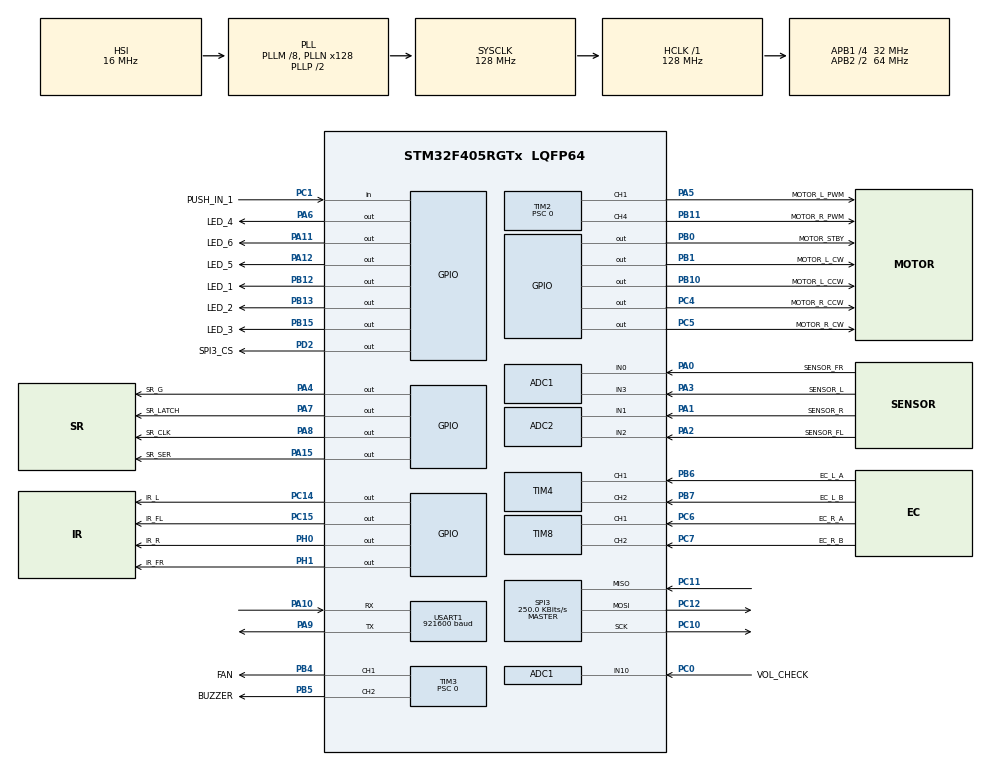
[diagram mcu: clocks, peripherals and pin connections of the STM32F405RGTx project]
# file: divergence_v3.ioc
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ADC1.Channel-0\#ChannelRegularConversion=ADC_CHANNEL_3
ADC1.Channel-1\#ChannelRegularConversion=ADC_CHANNEL_0
ADC1.Channel-2\#ChannelRegularConversion=ADC_CHANNEL_3
ADC1.Channel-3\#ChannelRegularConversion=ADC_CHANNEL_0
ADC1.Channel-4\#ChannelRegularConversion=ADC_CHANNEL_10
ADC1.ClockPrescaler=ADC_CLOCK_SYNC_PCLK_DIV4
ADC1.DiscontinuousConvMode=ENABLE
ADC1.NbrOfConversion=5
ADC1.NbrOfConversionFlag=1
ADC1.Rank-0\#ChannelRegularConversion=1
ADC1.Rank-1\#ChannelRegularConversion=2
ADC1.Rank-2\#ChannelRegularConversion=3
ADC1.Rank-3\#ChannelRegularConversion=4
ADC1.Rank-4\#ChannelRegularConversion=5
ADC1.SamplingTime-0\#ChannelRegularConversion=ADC_SAMPLETIME_84CYCLES
ADC1.SamplingTime-1\#ChannelRegularConversion=ADC_SAMPLETIME_84CYCLES
ADC1.SamplingTime-2\#ChannelRegularConversion=ADC_SAMPLETIME_84CYCLES
ADC1.SamplingTime-3\#ChannelRegularConversion=ADC_SAMPLETIME_84CYCLES
ADC1.SamplingTime-4\#ChannelRegularConversion=ADC_SAMPLETIME_84CYCLES
ADC1.ScanConvMode=ENABLE
ADC1.master=1
ADC2.Channel-0\#ChannelRegularConversion=ADC_CHANNEL_2
ADC2.Channel-1\#ChannelRegularConversion=ADC_CHANNEL_1
ADC2.Channel-2\#ChannelRegularConversion=ADC_CHANNEL_2
ADC2.Channel-3\#ChannelRegularConversion=ADC_CHANNEL_1
ADC2.ClockPrescaler=ADC_CLOCK_SYNC_PCLK_DIV4
ADC2.DiscontinuousConvMode=ENABLE
ADC2.NbrOfConversion=4
ADC2.NbrOfConversionFlag=1
ADC2.Rank-0\#ChannelRegularConversion=1
ADC2.Rank-1\#ChannelRegularConversion=2
ADC2.Rank-2\#ChannelRegularConversion=3
ADC2.Rank-3\#ChannelRegularConversion=4
ADC2.SamplingTime-0\#ChannelRegularConversion=ADC_SAMPLETIME_84CYCLES
ADC2.SamplingTime-1\#ChannelRegularConversion=ADC_SAMPLETIME_84CYCLES
ADC2.SamplingTime-2\#ChannelRegularConversion=ADC_SAMPLETIME_84CYCLES
ADC2.SamplingTime-3\#ChannelRegularConversion=ADC_SAMPLETIME_84CYCLES
ADC2.ScanConvMode=ENABLE
Dma.Request0=SPI3_RX
Dma.Request1=SPI3_TX
Dma.SPI3_RX.0.Direction=DMA_PERIPH_TO_MEMORY
Dma.SPI3_RX.0.FIFOMode=DMA_FIFOMODE_DISABLE
Dma.SPI3_RX.0.Instance=DMA1_Stream0
Dma.SPI3_RX.0.MemDataAlignment=DMA_MDATAALIGN_BYTE
Dma.SPI3_RX.0.MemInc=DMA_MINC_ENABLE
Dma.SPI3_RX.0.Mode=DMA_NORMAL
Dma.SPI3_RX.0.PeriphDataAlignment=DMA_PDATAALIGN_BYTE
Dma.SPI3_RX.0.PeriphInc=DMA_PINC_DISABLE
Dma.SPI3_RX.0.Priority=DMA_PRIORITY_VERY_HIGH
Dma.SPI3_TX.1.Direction=DMA_MEMORY_TO_PERIPH
Dma.SPI3_TX.1.FIFOMode=DMA_FIFOMODE_DISABLE
Dma.SPI3_TX.1.Instance=DMA1_Stream5
Dma.SPI3_TX.1.MemDataAlignment=DMA_MDATAALIGN_BYTE
Dma.SPI3_TX.1.MemInc=DMA_MINC_DISABLE
Dma.SPI3_TX.1.Mode=DMA_NORMAL
Dma.SPI3_TX.1.PeriphDataAlignment=DMA_PDATAALIGN_BYTE
Dma.SPI3_TX.1.PeriphInc=DMA_PINC_DISABLE
Dma.SPI3_TX.1.Priority=DMA_PRIORITY_VERY_HIGH
Mcu.Family=STM32F4
Mcu.Name=STM32F405RGTx
Mcu.Package=LQFP64
NVIC.DMA1_Stream0_IRQn=true\:0\:0\:false\:false\:true\:false\:true\:true
NVIC.DMA1_Stream5_IRQn=true\:0\:0\:false\:false\:true\:false\:true\:true
NVIC.PriorityGroup=NVIC_PRIORITYGROUP_4
NVIC.SPI3_IRQn=true\:0\:0\:false\:false\:true\:true\:true\:true
NVIC.TIM6_DAC_IRQn=true\:0\:0\:false\:false\:true\:true\:true\:true
PA0-WKUP.GPIO_Label=SENSOR_FR
PA0-WKUP.Signal=ADCx_IN0
PA1.GPIO_Label=SENSOR_R
PA1.Signal=ADCx_IN1
PA10.Mode=Asynchronous
PA10.Signal=USART1_RX
PA11.GPIO_Label=LED_6
PA11.Signal=GPIO_Output
PA12.GPIO_Label=LED_5
PA12.Signal=GPIO_Output
PA13.Signal=SYS_JTMS-SWDIO
PA14.Signal=SYS_JTCK-SWCLK
PA15.GPIO_Label=SR_SER
PA15.Signal=GPIO_Output
PA2.GPIO_Label=SENSOR_FL
PA2.Signal=ADCx_IN2
PA3.GPIO_Label=SENSOR_L
PA3.Signal=ADCx_IN3
PA4.GPIO_Label=SR_G
PA4.Signal=GPIO_Output
PA5.GPIO_Label=MOTOR_L_PWM
PA5.Signal=S_TIM2_CH1_ETR
PA6.GPIO_Label=LED_4
PA6.Signal=GPIO_Output
PA7.GPIO_Label=SR_LATCH
PA7.Signal=GPIO_Output
PA8.GPIO_Label=SR_CLK
PA8.Signal=GPIO_Output
PA9.Mode=Asynchronous
PA9.Signal=USART1_TX
PB0.GPIO_Label=MOTOR_STBY
PB0.Signal=GPIO_Output
PB1.GPIO_Label=MOTOR_L_CW
PB1.Signal=GPIO_Output
PB10.GPIO_Label=MOTOR_L_CCW
PB10.Signal=GPIO_Output
PB11.GPIO_Label=MOTOR_R_PWM
PB11.Signal=S_TIM2_CH4
PB12.GPIO_Label=LED_1
PB12.Signal=GPIO_Output
PB13.GPIO_Label=LED_2
PB13.Signal=GPIO_Output
PB15.GPIO_Label=LED_3
PB15.Signal=GPIO_Output
PB4.GPIO_Label=FAN
PB4.Signal=S_TIM3_CH1
PB5.GPIO_Label=BUZZER
PB5.Signal=S_TIM3_CH2
PB6.GPIO_Label=EC_L_A
PB6.Signal=S_TIM4_CH1
PB7.GPIO_Label=EC_L_B
PB7.Signal=S_TIM4_CH2
PC0.GPIO_Label=VOL_CHECK
PC0.Signal=ADCx_IN10
PC1.GPIO_Label=PUSH_IN_1
PC1.Signal=GPIO_Input
PC10.Mode=Full_Duplex_Master
PC10.Signal=SPI3_SCK
PC11.Mode=Full_Duplex_Master
PC11.Signal=SPI3_MISO
PC12.Mode=Full_Duplex_Master
PC12.Signal=SPI3_MOSI
PC14-OSC32_IN.GPIO_Label=IR_L
PC14-OSC32_IN.Signal=GPIO_Output
PC15-OSC32_OUT.GPIO_Label=IR_FL
PC15-OSC32_OUT.Signal=GPIO_Output
PC4.GPIO_Label=MOTOR_R_CCW
PC4.Signal=GPIO_Output
PC5.GPIO_Label=MOTOR_R_CW
PC5.Signal=GPIO_Output
PC6.GPIO_Label=EC_R_A
PC6.Signal=S_TIM8_CH1
PC7.GPIO_Label=EC_R_B
PC7.Signal=S_TIM8_CH2
PD2.GPIO_Label=SPI3_CS
PD2.Signal=GPIO_Output
PH0-OSC_IN.GPIO_Label=IR_R
PH0-OSC_IN.Signal=GPIO_Output
PH1-OSC_OUT.GPIO_Label=IR_FR
PH1-OSC_OUT.Signal=GPIO_Output
ProjectManager.HeapSize=0x200
ProjectManager.StackSize=0x400
ProjectManager.TargetToolchain=CMake
RCC.48MHZClocksFreq_Value=64000000
RCC.AHBFreq_Value=128000000
RCC.APB1CLKDivider=RCC_HCLK_DIV4
RCC.APB1Freq_Value=32000000
RCC.APB1TimFreq_Value=64000000
RCC.APB2CLKDivider=RCC_HCLK_DIV2
RCC.APB2Freq_Value=64000000
RCC.APB2TimFreq_Value=128000000
RCC.CortexFreq_Value=128000000
RCC.HCLKFreq_Value=128000000
RCC.HSE_VALUE=25000000
RCC.HSI_VALUE=16000000
RCC.LSE_VALUE=32768
RCC.PLLM=8
RCC.PLLN=128
RCC.SYSCLKFreq_VALUE=128000000
RCC.SYSCLKSource=RCC_SYSCLKSOURCE_PLLCLK
RCC.VCOOutputFreq_Value=256000000
SH.ADCx_IN0.0=ADC1_IN0,IN0
SH.ADCx_IN1.0=ADC2_IN1,IN1
SH.ADCx_IN10.0=ADC1_IN10,IN10
SH.ADCx_IN2.0=ADC2_IN2,IN2
SH.ADCx_IN3.0=ADC1_IN3,IN3
SH.S_TIM2_CH1_ETR.0=TIM2_CH1,PWM Generation1 CH1
SH.S_TIM2_CH4.0=TIM2_CH4,PWM Generation4 CH4
SH.S_TIM3_CH1.0=TIM3_CH1,PWM Generation1 CH1
SH.S_TIM3_CH2.0=TIM3_CH2,PWM Generation2 CH2
SH.S_TIM4_CH1.0=TIM4_CH1,Encoder_Interface
SH.S_TIM4_CH2.0=TIM4_CH2,Encoder_Interface
SH.S_TIM8_CH1.0=TIM8_CH1,Encoder_Interface
SH.S_TIM8_CH2.0=TIM8_CH2,Encoder_Interface
SPI3.BaudRatePrescaler=SPI_BAUDRATEPRESCALER_128
SPI3.CLKPhase=SPI_PHASE_2EDGE
SPI3.CLKPolarity=SPI_POLARITY_HIGH
SPI3.CalculateBaudRate=250.0 KBits/s
SPI3.Direction=SPI_DIRECTION_2LINES
SPI3.Mode=SPI_MODE_MASTER
SPI3.VirtualType=VM_MASTER
TIM2.Channel-PWM\ Generation1\ CH1=TIM_CHANNEL_1
TIM2.Channel-PWM\ Generation4\ CH4=TIM_CHANNEL_4
TIM2.OCMode_PWM-PWM\ Generation1\ CH1=TIM_OCMODE_PWM1
TIM2.Period=1000-1
TIM2.Prescaler=0
TIM3.Channel-PWM\ Generation1\ CH1=TIM_CHANNEL_1
TIM3.Channel-PWM\ Generation2\ CH2=TIM_CHANNEL_2
TIM3.Period=1000-1
TIM3.Prescaler=0
TIM4.EncoderMode=TIM_ENCODERMODE_TI12
TIM6.Period=1000-1
TIM6.Prescaler=64-1
TIM8.EncoderMode=TIM_ENCODERMODE_TI12
USART1.BaudRate=921600
USART1.VirtualMode=VM_ASYNC
VP_CRC_VS_CRC.Mode=CRC_Activate
VP_TIM2_VS_ClockSourceINT.Mode=Internal
VP_TIM3_VS_ClockSourceINT.Mode=Internal
VP_TIM6_VS_ClockSourceINT.Mode=Enable_Timer
board=custom

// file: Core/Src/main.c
/* USER CODE BEGIN Header */
/**
  ******************************************************************************
  * @file           : main.c
  * @brief          : Main program body
  ******************************************************************************
  * @attention
  *
  * Copyright (c) 2026 STMicroelectronics.
  * All rights reserved.
  *
  * This software is licensed under terms that can be found in the LICENSE file
  * in the root directory of this software component.
  * If no LICENSE file comes with this software, it is provided AS-IS.
  *
  ******************************************************************************
  */
/* USER CODE END Header */
#include "main.h"
#include "adc.h"
#include "crc.h"
#include "dma.h"
#include "spi.h"
#include "tim.h"
#include "usart.h"
#include "gpio.h"

/* USER CODE BEGIN Includes */
#include "app/app_main.hpp"
/* USER CODE END Includes */

void SystemClock_Config(void);

int main(void)
{

  /* MCU Configuration--------------------------------------------------------*/

  /* Reset of all peripherals, Initializes the Flash interface and the Systick. */
  HAL_Init();

  /* Configure the system clock */
  SystemClock_Config();

  /* Initialize all configured peripherals */
  MX_GPIO_Init();
  MX_DMA_Init();
  MX_ADC1_Init();
  MX_TIM2_Init();
  MX_TIM3_Init();
  MX_TIM4_Init();
  MX_TIM8_Init();
  MX_USART1_UART_Init();
  MX_SPI3_Init();
  MX_ADC2_Init();
  MX_TIM6_Init();
  MX_CRC_Init();
  /* USER CODE BEGIN 2 */
  app_main();
  /* USER CODE END 2 */

  /* Infinite loop */
  while (1)
  {

  }
}

void SystemClock_Config(void)
{
  RCC_OscInitTypeDef RCC_OscInitStruct = {0};
  RCC_ClkInitTypeDef RCC_ClkInitStruct = {0};

  /** Configure the main internal regulator output voltage
  */
  __HAL_RCC_PWR_CLK_ENABLE();
  __HAL_PWR_VOLTAGESCALING_CONFIG(PWR_REGULATOR_VOLTAGE_SCALE1);

  /** Initializes the RCC Oscillators according to the specified parameters
  * in the RCC_OscInitTypeDef structure.
  */
  RCC_OscInitStruct.OscillatorType = RCC_OSCILLATORTYPE_HSI;
  RCC_OscInitStruct.HSIState = RCC_HSI_ON;
  RCC_OscInitStruct.HSICalibrationValue = RCC_HSICALIBRATION_DEFAULT;
  RCC_OscInitStruct.PLL.PLLState = RCC_PLL_ON;
  RCC_OscInitStruct.PLL.PLLSource = RCC_PLLSOURCE_HSI;
  RCC_OscInitStruct.PLL.PLLM = 8;
  RCC_OscInitStruct.PLL.PLLN = 128;
  RCC_OscInitStruct.PLL.PLLP = RCC_PLLP_DIV2;
  RCC_OscInitStruct.PLL.PLLQ = 4;
  if (HAL_RCC_OscConfig(&RCC_OscInitStruct) != HAL_OK)
  {
    Error_Handler();
  }

  /** Initializes the CPU, AHB and APB buses clocks
  */
  RCC_ClkInitStruct.ClockType = RCC_CLOCKTYPE_HCLK|RCC_CLOCKTYPE_SYSCLK
                              |RCC_CLOCKTYPE_PCLK1|RCC_CLOCKTYPE_PCLK2;
  RCC_ClkInitStruct.SYSCLKSource = RCC_SYSCLKSOURCE_PLLCLK;
  RCC_ClkInitStruct.AHBCLKDivider = RCC_SYSCLK_DIV1;
  RCC_ClkInitStruct.APB1CLKDivider = RCC_HCLK_DIV4;
  RCC_ClkInitStruct.APB2CLKDivider = RCC_HCLK_DIV2;

  if (HAL_RCC_ClockConfig(&RCC_ClkInitStruct, FLASH_LATENCY_4) != HAL_OK)
  {
    Error_Handler();
  }
}

void Error_Handler(void)
{
  __disable_irq();
  while (1)
  {
  }
}
